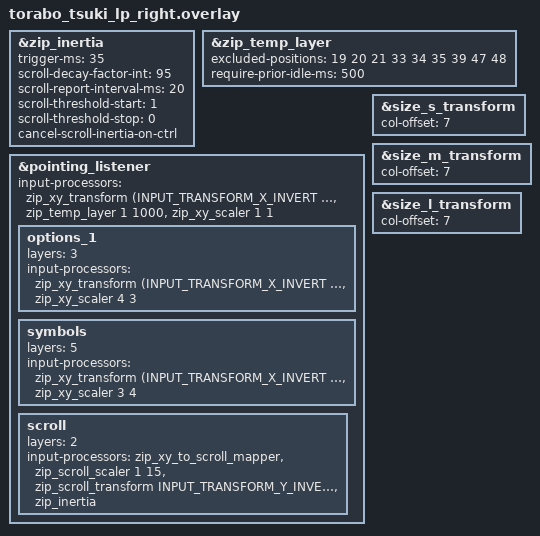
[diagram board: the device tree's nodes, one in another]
#include "torabo_tsuki_lp.dtsi"
#include <input/processors.dtsi>
#include <dt-bindings/zmk/input_transform.h>
#include <zmk-input-inertia/input/processor/input_inertia.dtsi>

&zip_inertia {
    // 慣性が始まるまでの待ち時間 (推奨: センサーのポーリングレートの2倍以上)
    trigger-ms = <35>; // ms

    // --- スクロールの設定 ---
    scroll-decay-factor-int = <95>;    // スクロール減衰率
    scroll-report-interval-ms = <20>;  // スクロールレポート間隔 (ms)
    scroll-threshold-start = <1>;      // 慣性が発動する最小スクロール量 (pix/report)
    scroll-threshold-stop = <0>;       // 慣性が停止するスクロール量 (pix/report)

    // 任意: Ctrl 押下中はスクロール慣性を停止/抑止する
    cancel-scroll-inertia-on-ctrl;
};

&zip_temp_layer {
    excluded-positions = < 
        // https://zmk-physical-layout-converter.streamlit.app/
        19 20 21
        33 34 35
        39
        47 48
    >;

    require-prior-idle-ms = <500>;
};

&pointing_listener {
    input-processors = <
        &zip_xy_transform (INPUT_TRANSFORM_X_INVERT | INPUT_TRANSFORM_Y_INVERT)
        &zip_temp_layer 1 1000
        &zip_xy_scaler 1 1
    >;

    options_1 {
        layers = <3>;
        input-processors = <
            &zip_xy_transform (INPUT_TRANSFORM_X_INVERT | INPUT_TRANSFORM_Y_INVERT)
            &zip_xy_scaler 4 3
        >;        
    };

    symbols {
        layers = <5>;
        input-processors = <
            &zip_xy_transform (INPUT_TRANSFORM_X_INVERT | INPUT_TRANSFORM_Y_INVERT)
            &zip_xy_scaler 3 4
        >;        
    };
    
    scroll {
        layers = <2>;
        input-processors = <
            &zip_xy_to_scroll_mapper
            &zip_scroll_scaler 1 15
            &zip_scroll_transform INPUT_TRANSFORM_Y_INVERT
        >, <&zip_inertia>;
    };
};

&size_s_transform {
    col-offset = <7>;
};

&size_m_transform {
    col-offset = <7>;
};

&size_l_transform {
    col-offset = <7>;
};
